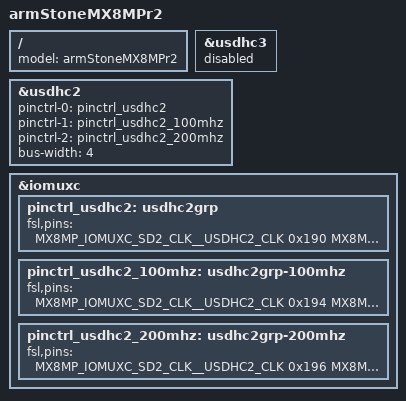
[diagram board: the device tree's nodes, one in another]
/*
* Copyright 2026 F&S Elektronik Systeme GmbH
*
* This program is free software; you can redistribute it and/or
* modify it under the terms of the GNU General Public License
* as published by the Free Software Foundation; either version 2
* of the License, or (at your option) any later version.
*
* This program is distributed in the hope that it will be useful,
* but WITHOUT ANY WARRANTY; without even the implied warranty of
* MERCHANTABILITY or FITNESS FOR A PARTICULAR PURPOSE.  See the
* GNU General Public License for more details.
*/

/dts-v1/;

#include "armstonemx8mp.dts"

/ {
	model = "armStoneMX8MPr2";
};

/* SD_A - WLAN for armStoneMX8MPr2 */
&usdhc3 {
	status = "disabled";
};

/* SD_B - internal Micro-SD */
&usdhc2 {
	pinctrl-names = "default", "state_100mhz", "state_200mhz";
	pinctrl-0 = <&pinctrl_usdhc2>;
	pinctrl-1 = <&pinctrl_usdhc2_100mhz>;
	pinctrl-2 = <&pinctrl_usdhc2_200mhz>;
	bus-width = <4>;
	status = "okay";
};

&iomuxc {
	pinctrl_usdhc2: usdhc2grp {
		fsl,pins = <
			MX8MP_IOMUXC_SD2_CLK__USDHC2_CLK	0x190
			MX8MP_IOMUXC_SD2_CMD__USDHC2_CMD	0x1d0
			MX8MP_IOMUXC_SD2_DATA0__USDHC2_DATA0	0x1d0
			MX8MP_IOMUXC_SD2_DATA1__USDHC2_DATA1	0x1d0
			MX8MP_IOMUXC_SD2_DATA2__USDHC2_DATA2	0x1d0
			MX8MP_IOMUXC_SD2_DATA3__USDHC2_DATA3	0x1d0
			MX8MP_IOMUXC_SD2_CD_B__USDHC2_CD_B	0x084
			MX8MP_IOMUXC_GPIO1_IO04__USDHC2_VSELECT 0x0c1
		>;
	};

	pinctrl_usdhc2_100mhz: usdhc2grp-100mhz {
		fsl,pins = <
			MX8MP_IOMUXC_SD2_CLK__USDHC2_CLK	0x194
			MX8MP_IOMUXC_SD2_CMD__USDHC2_CMD	0x1d4
			MX8MP_IOMUXC_SD2_DATA0__USDHC2_DATA0	0x1d4
			MX8MP_IOMUXC_SD2_DATA1__USDHC2_DATA1	0x1d4
			MX8MP_IOMUXC_SD2_DATA2__USDHC2_DATA2	0x1d4
			MX8MP_IOMUXC_SD2_DATA3__USDHC2_DATA3	0x1d4
			MX8MP_IOMUXC_SD2_CD_B__USDHC2_CD_B	0x084
			MX8MP_IOMUXC_GPIO1_IO04__USDHC2_VSELECT 0x0c1
		>;
	};

	pinctrl_usdhc2_200mhz: usdhc2grp-200mhz {
		fsl,pins = <
			MX8MP_IOMUXC_SD2_CLK__USDHC2_CLK	0x196
			MX8MP_IOMUXC_SD2_CMD__USDHC2_CMD	0x1d6
			MX8MP_IOMUXC_SD2_DATA0__USDHC2_DATA0	0x1d6
			MX8MP_IOMUXC_SD2_DATA1__USDHC2_DATA1	0x1d6
			MX8MP_IOMUXC_SD2_DATA2__USDHC2_DATA2	0x1d6
			MX8MP_IOMUXC_SD2_DATA3__USDHC2_DATA3	0x1d6
			MX8MP_IOMUXC_SD2_CD_B__USDHC2_CD_B	0x084
			MX8MP_IOMUXC_GPIO1_IO04__USDHC2_VSELECT 0x0c1
		>;
	};
};
